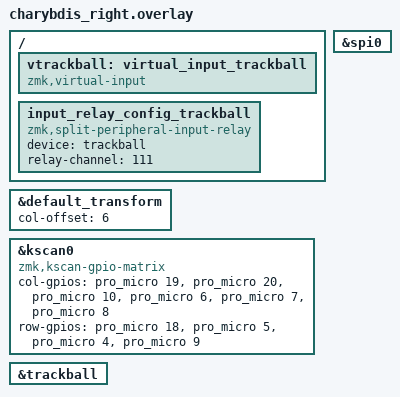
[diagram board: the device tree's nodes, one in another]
#include "charybdis.dtsi"
#include "charybdis_pmw3610.dtsi"

// The matrix transform is 6 columns over because the left half is 6 columns wide.
&default_transform {
	col-offset = <6>;
};

&kscan0 {
	compatible = "zmk,kscan-gpio-matrix";
	col-gpios
		= <&pro_micro 19 (GPIO_ACTIVE_HIGH | GPIO_PULL_DOWN)>
		, <&pro_micro 20 (GPIO_ACTIVE_HIGH | GPIO_PULL_DOWN)>
		, <&pro_micro 10 (GPIO_ACTIVE_HIGH | GPIO_PULL_DOWN)>
		, <&pro_micro 6 (GPIO_ACTIVE_HIGH | GPIO_PULL_DOWN)>
		, <&pro_micro 7 (GPIO_ACTIVE_HIGH | GPIO_PULL_DOWN)>
		, <&pro_micro 8 (GPIO_ACTIVE_HIGH | GPIO_PULL_DOWN)>
		;

		row-gpios
			= <&pro_micro 18 GPIO_ACTIVE_HIGH>
			, <&pro_micro 5 GPIO_ACTIVE_HIGH>
			, <&pro_micro 4 GPIO_ACTIVE_HIGH>
			, <&pro_micro 9 GPIO_ACTIVE_HIGH>
            ;
};

&spi0 {
    status = "okay";
};

&trackball {
    status = "okay";
};

/ {
	vtrackball: virtual_input_trackball {
		compatible = "zmk,virtual-input";
	};

	input_relay_config_trackball {
		compatible = "zmk,split-peripheral-input-relay";
		device = <&trackball>;
		relay-channel = <111>;
	};
};

// &pd0 {
// 	status = "okay";
// 	/* the rest of sensor config should be config here, e.g. gpios */
// };

// / {
// 	/* THIS make keymap binding happy only, nothing happen on peripheral side */
// 	pd1: virtual_input {
// 		compatible = "zmk,virtual-input";
// 	};

// 	/* for peripheral side, define (input-device)-to-(relay-channel) mapping */
// 	input_relay_config_111 {
// 		compatible = "zmk,split-peripheral-input-relay";

// 		/* peripheral side input device, used to... */
// 		/*  - be intecepted on peripheral; */
// 		/*  - and then, be resurrected as `zmk,virtual-device` on central; */
// 		device = <&pd0>;
		
// 		/* channel id, used to be be transfered along with all input events. */
// 		/* NOTE 1: pick any 8bit integer. (1 - 255) */
// 		/* NOTE 2: should matching relay-channel on central overlay */
// 		relay-channel = <111>;
// 	};
// };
